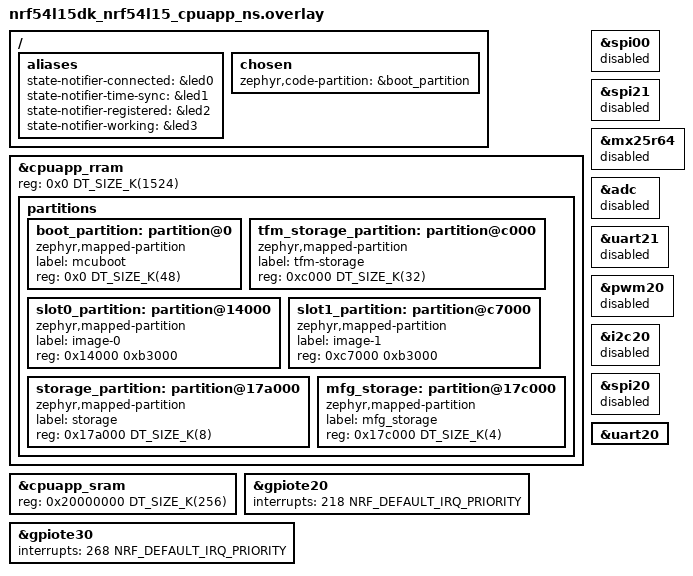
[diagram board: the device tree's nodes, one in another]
/*
 * Copyright (c) 2026 Nordic Semiconductor ASA
 *
 * SPDX-License-Identifier: LicenseRef-Nordic-5-Clause
 */

 /{
	aliases {
		state-notifier-connected = &led0;
		state-notifier-time-sync = &led1;
		state-notifier-registered = &led2;
		state-notifier-working = &led3;
	};

	chosen {
		zephyr,code-partition = &boot_partition;
	};
};

&cpuapp_rram {
	reg = <0x0 DT_SIZE_K(1524)>;
};

&cpuapp_sram {
	reg = <0x20000000 DT_SIZE_K(256)>;
	ranges = <0x0 0x20000000  0x40000>;
};

/delete-node/ &boot_partition;
/delete-node/ &slot0_partition;
/delete-node/ &slot1_partition;
/delete-node/ &storage_partition;

&cpuapp_rram {
	partitions {
		ranges;
		#address-cells = <1>;
		#size-cells = <1>;

		boot_partition: partition@0 {
			compatible = "zephyr,mapped-partition";
			label = "mcuboot";
			reg = <0x0 DT_SIZE_K(48)>;
		};

		tfm_storage_partition: partition@c000 {
			compatible = "zephyr,mapped-partition";
			label = "tfm-storage";
			reg = <0xc000 DT_SIZE_K(32)>;
		};

		slot0_partition: partition@14000 {
			compatible = "zephyr,mapped-partition";
			label = "image-0";
			reg = <0x14000 0xb3000>;
		};

		slot1_partition: partition@c7000 {
			compatible = "zephyr,mapped-partition";
			label = "image-1";
			reg = <0xc7000 0xb3000>;
		};

		storage_partition: partition@17a000 {
			compatible = "zephyr,mapped-partition";
			label = "storage";
			reg = <0x17a000 DT_SIZE_K(8)>;
		};

		mfg_storage: partition@17c000 {
			compatible = "zephyr,mapped-partition";
			label = "mfg_storage";
			reg = <0x17c000 DT_SIZE_K(4)>;
		};
	};
};

&spi00 {
	status = "disabled";
};

&spi21 {
	status = "disabled";
};

/* Secondary slot is in internal RRAM - disable external flash for MCUboot */
&mx25r64 {
	status = "disabled";
};

&adc {
	status = "disabled";
};
&uart21 {
	status = "disabled";
};
&pwm20 {
	status = "disabled";
};
&i2c20 {
	status = "disabled";
};
&spi20 {
	status = "disabled";
};

// TODO: re-enable HWFC once it's fixed
&uart20 {
	/delete-property/ hw-flow-control;
};


// Change IRQ ids to handle button interrupts.

// The default values for nRF54L15 are 219 and 269,
// but with TF-M they are reserved for the secure domain
// (218 and 268 are reserved for the non-secure domain).
&gpiote20 {
	interrupts = <218 NRF_DEFAULT_IRQ_PRIORITY>;
};

&gpiote30 {
	interrupts = <268 NRF_DEFAULT_IRQ_PRIORITY>;
};
